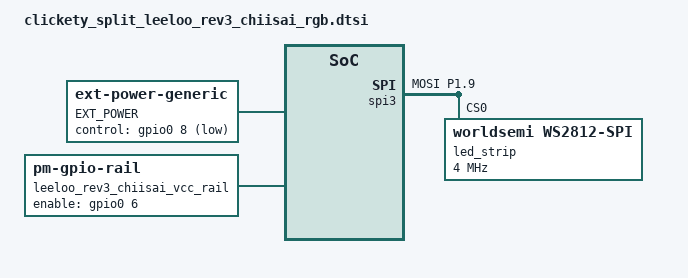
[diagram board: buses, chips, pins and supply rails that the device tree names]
/*
 * Copyright (c) 2026 Clickety Split Ltd.
 * SPDX-License-Identifier: MIT
 */

#include <dt-bindings/gpio/gpio.h>
#include <dt-bindings/led/led.h>
#include <zephyr/dt-bindings/pinctrl/nrf-pinctrl.h>

/ {
    chosen {
        zmk,underglow = &led_strip;
    };

    EXT_POWER {
        compatible = "zmk,ext-power-generic";
        control-gpios = <&gpio0 8 GPIO_ACTIVE_LOW>;

        init-delay-ms = <50>;
    };
};

/*
 * The PM-aware GPIO rail keeps the Chiisai LDO enabled during
 * normal operation and ordinary idle.
 *
 * After ZMK EXT_POWER is redirected to P0.08, P0.06 independently supplies
 * VCC for the display and the source side of the RGB MOSFET. Device PM
 * releases P0.06 before deep sleep and restores it on wake.
 */
/ {
    /*
     * Keep Chiisai VCC available during active use and ordinary ZMK idle.
     */
    leeloo_rev3_chiisai_vcc_rail: leeloo-rev3-chiisai-vcc-rail {
        compatible = "zmk,pm-gpio-rail";
        enable-gpios = <&gpio0 6 GPIO_ACTIVE_HIGH>;
        init-delay-ms = <50>;
        status = "okay";
    };
};

&pinctrl {
    leeloo_rev3_chiisai_spi3_default:
        leeloo_rev3_chiisai_spi3_default {
        group1 {
            psels = <NRF_PSEL(SPIM_MOSI, 1, 9)>;
        };
    };

    leeloo_rev3_chiisai_spi3_sleep:
        leeloo_rev3_chiisai_spi3_sleep {
        group1 {
            psels = <NRF_PSEL(SPIM_MOSI, 1, 9)>;
            low-power-enable;
        };
    };
};

&spi3 {
    compatible = "nordic,nrf-spim";
    status = "okay";

    pinctrl-0 = <&leeloo_rev3_chiisai_spi3_default>;
    pinctrl-1 = <&leeloo_rev3_chiisai_spi3_sleep>;
    pinctrl-names = "default", "sleep";

    led_strip: ws2812@0 {
        compatible = "worldsemi,ws2812-spi";
        status = "okay";

        reg = <0>;
        spi-max-frequency = <4000000>;

        chain-length = <29>;
        spi-one-frame = <0x70>;
        spi-zero-frame = <0x40>;

        color-mapping = <
            LED_COLOR_ID_GREEN
            LED_COLOR_ID_RED
            LED_COLOR_ID_BLUE
        >;
    };
};
